# aif2 register map
Vendor: Texas Instruments
Registers are 32-bit, read-write, no defined reset value unless marked. A register's access mark holds for its fields unless they carry their own. Offsets are as the file gives them; [hi:lo] are bit positions; {n}, {i} and the like mark numbered series; 'fields as' and 'values as' point back to an identical list.

## AIF2 (part 3 of 3)
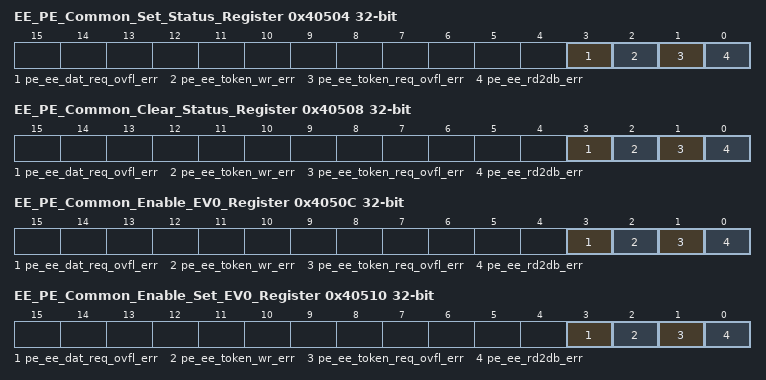
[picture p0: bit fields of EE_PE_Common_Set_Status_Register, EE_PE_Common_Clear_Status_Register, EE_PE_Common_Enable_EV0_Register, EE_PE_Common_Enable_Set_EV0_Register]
0x40504 EE_PE_Common_Set_Status_Register wo
  [3] pe_ee_dat_req_ovfl_err — PE data register overflow error Set.
  [2] pe_ee_token_wr_err — PE token write error Set.
  [1] pe_ee_token_req_ovfl_err — PE token register overflow error Set.
  [0] pe_ee_rd2db_err — PE read to DB error Set.
0x40508 EE_PE_Common_Clear_Status_Register wo
  [3] pe_ee_dat_req_ovfl_err — PE data register overflow error Clear.
  [2] pe_ee_token_wr_err — PE token write error Clear.
  [1] pe_ee_token_req_ovfl_err — PE token register overflow error Clear.
  [0] pe_ee_rd2db_err — PE read to DB error Clear.
0x4050C EE_PE_Common_Enable_EV0_Register ro — EE PE Common Enable EVO Register
  [3] pe_ee_dat_req_ovfl_err — PE data register overflow error Enable.
  [2] pe_ee_token_wr_err — PE token write error Enable.
  [1] pe_ee_token_req_ovfl_err — PE token register overflow error Enable.
  [0] pe_ee_rd2db_err — PE read to DB error Enable.
0x40510 EE_PE_Common_Enable_Set_EV0_Register wo
  fields as EE_PE_Common_Set_Status_Register
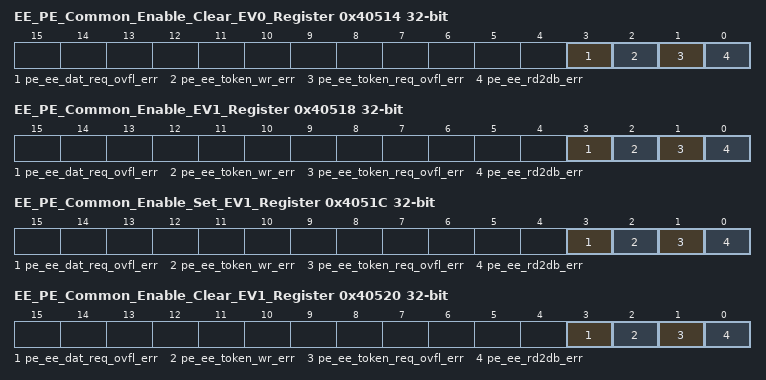
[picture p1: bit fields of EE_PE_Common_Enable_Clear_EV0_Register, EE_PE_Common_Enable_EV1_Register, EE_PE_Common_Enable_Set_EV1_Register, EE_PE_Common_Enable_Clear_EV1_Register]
0x40514 EE_PE_Common_Enable_Clear_EV0_Register wo
  fields as EE_PE_Common_Clear_Status_Register
0x40518 EE_PE_Common_Enable_EV1_Register ro
  fields as EE_PE_Common_Enable_EV0_Register
0x4051C EE_PE_Common_Enable_Set_EV1_Register wo
  [3] pe_ee_dat_req_ovfl_err — PE data register overflow error Enable Set.
  [2] pe_ee_token_wr_err — PE token write error Enable Set.
  [1] pe_ee_token_req_ovfl_err — PE token register overflow error Enable Set.
  [0] pe_ee_rd2db_err — PE read to DB error Enable Set.
0x40520 EE_PE_Common_Enable_Clear_EV1_Register wo
  [3] pe_ee_dat_req_ovfl_err — PE data register overflow error Enable Clear.
  [2] pe_ee_token_wr_err — PE token write error Enable Clear.
  [1] pe_ee_token_req_ovfl_err — PE token register overflow error Enable Clear.
  [0] pe_ee_rd2db_err — PE read to DB error Enable Clear.
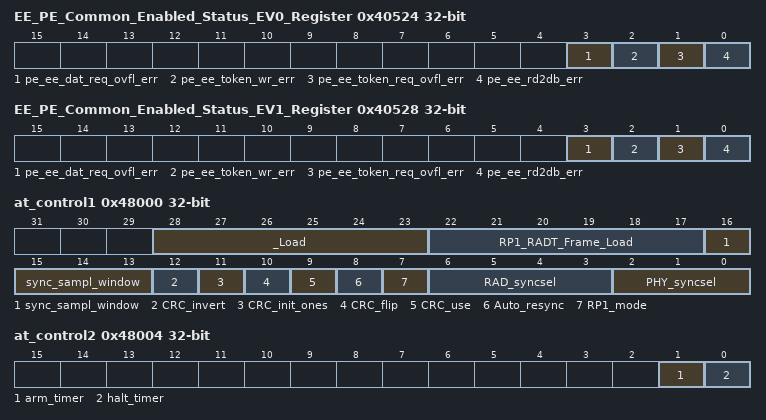
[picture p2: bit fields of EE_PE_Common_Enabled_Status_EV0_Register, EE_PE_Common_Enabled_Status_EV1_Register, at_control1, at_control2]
0x40524 EE_PE_Common_Enabled_Status_EV0_Register ro
  [3] pe_ee_dat_req_ovfl_err — PE data register overflow error Enabled.
  [2] pe_ee_token_wr_err — PE token write error Enabled.
  [1] pe_ee_token_req_ovfl_err — PE token register overflow error Enabled.
  [0] pe_ee_rd2db_err — PE read to DB error Enabled.
0x40528 EE_PE_Common_Enabled_Status_EV1_Register ro
  fields as EE_PE_Common_Enabled_Status_EV0_Register
0x48000 at_control1
  [28:23] _Load — RP1 PHYT Frame Load value =size +8
  [22:17] RP1_RADT_Frame_Load — RP1 RADT Frame Load value =size +8
  [16:13] sync_sampl_window — + or
  [12] CRC_invert
  [11] CRC_init_ones
  [10] CRC_flip — RP1 mode
  [9] CRC_use — CRC flip
  [8] Auto_resync — Auto resync if new frame boundary is received
  [7] RP1_mode
  [6:3] RAD_syncsel
  [2:0] PHY_syncsel
0x48004 at_control2
  [1] arm_timer, [0] halt_timer
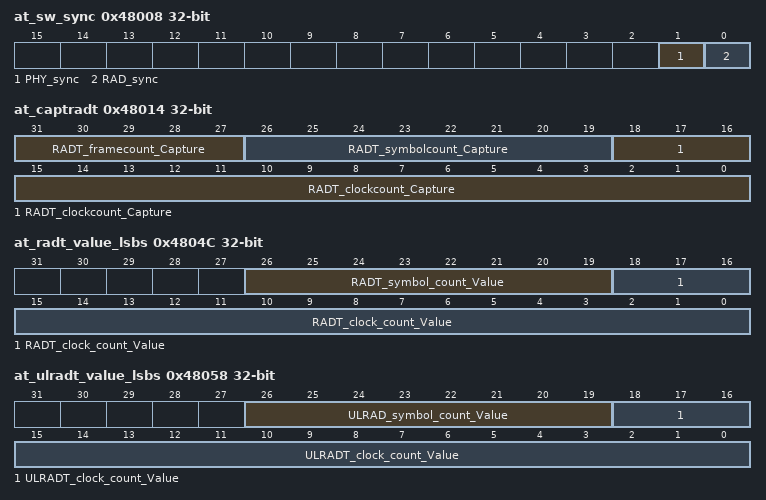
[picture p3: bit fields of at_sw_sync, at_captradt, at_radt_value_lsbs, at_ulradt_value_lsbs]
0x48008 at_sw_sync wo
  [1] PHY_sync, [0] RAD_sync
0x4800C at_phyt_cmp_radsync — at phyt radsync compare
  [21:0] RP1_RAD_Type_Select — PHYT_CMP PHYT compare value to produce a RADT sync when slected
0x48010 at_rp1_type
  [7:0] RP1_RAD_Type_Select
0x48014 at_captradt ro — Capture RADT clock and symbol and 5bit frame lsb counts on PHYT frame boundary
  [31:27] RADT_framecount_Capture — Capture RADT frame count 5lsbs upon a PHYT frame boundary
  [26:19] RADT_symbolcount_Capture — Capture RADT symbol count upon a PHYT frame boundary
  [18:0] RADT_clockcount_Capture — Capture RADT clock count upon a PHYT frame boundary
0x48020 at_rp1_type_capture ro
  [7:0] RP1_Type_Captured
0x48024 at_rp1_tod_capture_l ro
  [31:0] RP1_TOD_Capture_LSBs
0x48028 at_rp1_tod_capture_h ro
  [31:0] RP1_TOD_Capture_MSBs
0x4802C at_rp1_rp3_capture_l ro
  [31:0] RP1_RP3_Capture_LSBs
0x48030 at_rp1_rp3_capture_h ro
  [31:0] RP1_RP3_Capture_MSBs
0x48034 at_rp1_rad_capture_l ro
  [31:0] RP1_RADIO_System_Capture_LSBs
0x48038 at_rp1_rad_capture_h ro
  [31:0] RP1_RADIO_System_Capture_MSBs
0x48040 at_phyt_clkcnt_value ro
  [23:0] PHYT_clock_count_Value — PHYT clock count Value, 2 lsbs are always 00
0x48044 at_phyt_frm_value_lsbs ro
  [11:0] PHYT_Frame_Value_LSBs
0x48048 at_phyt_frm_value_msbs ro
  [27:0] PHYT_Frame_Value_MSBs
0x4804C at_radt_value_lsbs ro
  [26:19] RADT_symbol_count_Value, [18:0] RADT_clock_count_Value
0x48050 at_radt_value_mid ro
  [11:0] RADT_Frame_Value_LSBs
0x48054 at_radt_value_msbs ro
  [27:0] RADT_Frame_Value_MSBs
0x48058 at_ulradt_value_lsbs ro
  [26:19] ULRAD_symbol_count_Value — ULRADT symbol count Values
  [18:0] ULRADT_clock_count_Value
0x4805C at_ulradt_value_mid ro
  [11:0] ULRADT_Frame_Value_LSBs
0x48060 at_ulradt_value_msbs ro
  [27:0] ULRADT_Frame_Value_MSBs
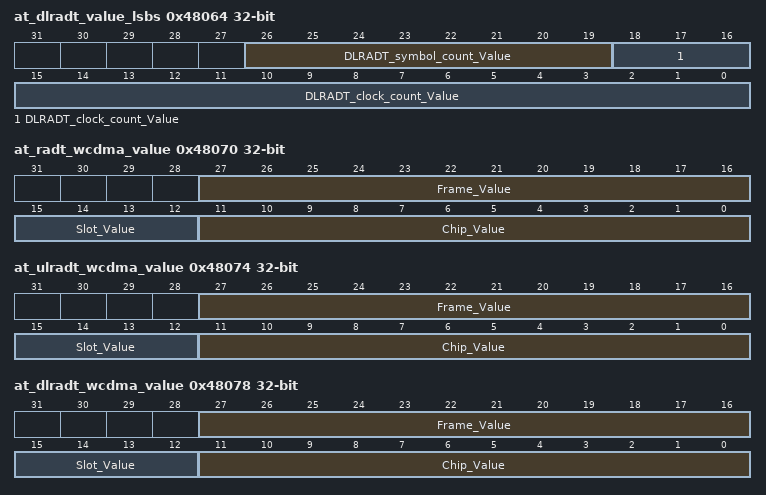
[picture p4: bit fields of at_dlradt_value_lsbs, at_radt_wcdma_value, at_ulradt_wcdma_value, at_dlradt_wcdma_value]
0x48064 at_dlradt_value_lsbs ro
  [26:19] DLRADT_symbol_count_Value, [18:0] DLRADT_clock_count_Value
0x48068 at_dlradt_value_mid ro
  [11:0] DLRADT_Frame_Value_LSBs
0x4806C at_dlradt_value_msbs ro
  [27:0] DLRADT_Frame_Value_MSBs
0x48070 at_radt_wcdma_value ro
  [27:16] Frame_Value, [15:12] Slot_Value, [11:0] Chip_Value
0x48074 at_ulradt_wcdma_value ro
  [27:16] Frame_Value, [15:12] Slot_Value, [11:0] Chip_Value
0x48078 at_dlradt_wcdma_value ro
  [27:16] Frame_Value, [15:12] Slot_Value, [11:0] Chip_Value
0x4807C at_radt_wcdma_div — at radt wcdma clock divider terminal count.
  [6:0] terminal_count — at radt wcdma clock divider terminal count. This counter divides dualbyte clock down to 3.84MHz chip rate for wcdma counters
0x48080 at_phyt_init_lsbs
  [21:0] PHYT_clock_count_Init
0x48084 at_phyt_init_mid
  [11:0] PHYT_Frame_Init_LSBs
0x48088 at_phyt_init_msbs
  [27:0] PHYT_Frame_Init_MSBs
0x4808C at_phyt_tc_lsbs
  [21:0] PHYT_Clock_Counter_TC
0x48090 at_phyt_frame_tc_lsbs
  [31:0] PHYT_Frame_TC_LSBs
0x48094 at_phyt_frame_tc_msbs
  [7:0] PHYT_Frame_TC_MSBs
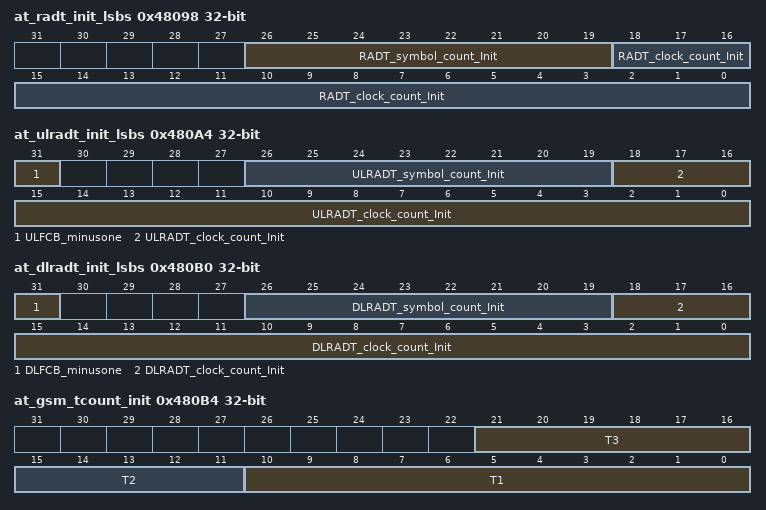
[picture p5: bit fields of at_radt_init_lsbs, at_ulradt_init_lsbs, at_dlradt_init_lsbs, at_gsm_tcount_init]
0x48098 at_radt_init_lsbs
  [26:19] RADT_symbol_count_Init, [18:0] RADT_clock_count_Init
0x4809C at_radt_init_mid
  [11:0] RADT_Frame_Init_LSBs
0x480A0 at_radt_init_msbs
  [27:0] RADT_Frame_Init_MSBs
0x480A4 at_ulradt_init_lsbs
  [31] ULFCB_minusone, [26:19] ULRADT_symbol_count_Init, [18:0] ULRADT_clock_count_Init
0x480A8 at_radt_tstamp_value ro
  [24:0] RADT_Tstamp_clock_counter_value
0x480B0 at_dlradt_init_lsbs
  [31] DLFCB_minusone, [26:19] DLRADT_symbol_count_Init, [18:0] DLRADT_clock_count_Init
0x480B4 at_gsm_tcount_init — at_gsm_tcount initialization
  [21:16] T3 — T3 w=init, affects at_gsm_tcount_value
  [15:11] T2 — T2 w=init, affects at_gsm_tcount_value
  [10:0] T1 — T1 w=init, affects at_gsm_tcount_value
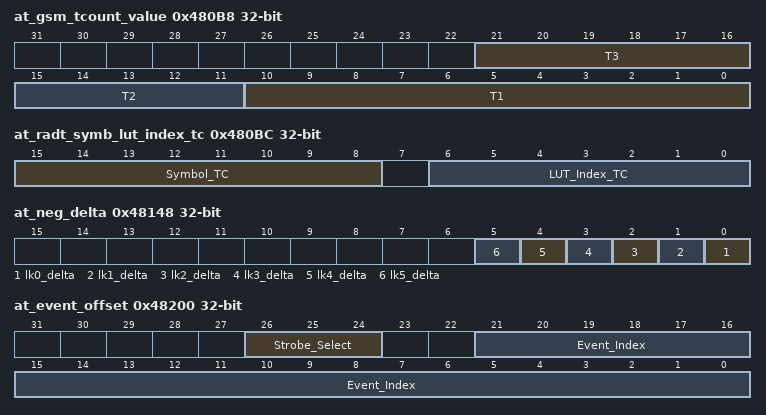
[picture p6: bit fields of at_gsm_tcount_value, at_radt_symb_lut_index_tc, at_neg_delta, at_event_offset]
0x480B8 at_gsm_tcount_value ro
  [21:16] T3 — T3 r=value of T3 counter
  [15:11] T2 — T2 r=value of T2 counter
  [10:0] T1 — T1 r=value of T1 counter
0x480BC at_radt_symb_lut_index_tc
  [15:8] Symbol_TC, [6:0] LUT_Index_TC
0x480C8 at_radt_frame_tc_lsbs — at_radt_frame_tc_msbs
  [31:0] RADT_Frame_TC_LSBs
0x480CC at_radt_frame_tc_msbs — at_radt_frame_tc_lsbs
  [7:0] RADT_Frame_TC_MSBs
0x480E0 at_ulradt_init_mid
  [11:0] RADT_Frame_Init_LSBs
0x480E4 at_ulradt_init_msbs
  [27:0] RADT_Frame_Init_MSBs
0x480E8 at_dlradt_init_mid
  [11:0] RADT_Frame_Init_LSBs
0x480EC at_dlradt_init_msbs
  [27:0] RADT_Frame_Init_MSBs
0x480F4 at_radt_init_lut_index — at_radt LUT Index initial value
  [6:0] LUT_Index_Init — LUT Index initial value
0x480F8 at_ulradt_init_lut_index — at_ulradt LUT Index initial value
  [6:0] LUT_Index_Init — LUT Index initial value
0x480FC at_dlradt_init_lut_index — at_dlradt LUT Index initial value
  [6:0] LUT_Index_Init — LUT Index initial value
0x48100 at_pimax_lk — (1 of 6, stride 12)
  [21:0] PI_max
0x48104 at_pimin_lk — (1 of 6, stride 12)
  [21:0] PI_min
0x48108 at_pivalue_lk ro — (1 of 6, stride 12)
  [21:0] PI_captured_value
0x48148 at_neg_delta — Negative delta control
  [n] lk{n}_delta (n=0..5) — Control for positive or negative delta for TM delta event. Controls the BFN PHYT frame number passed to the TM when the Delta event occurs
0x481F8 at_evt_enable
  [10:0] EVENT_Enable
0x481FC at_evt_force wo
  [10:0] EVENT_Force
0x48200 at_event_offset — (1 of 11, stride 16)
  [26:24] Strobe_Select
  [21:0] Event_Index — Event Offset Index
0x48204 at_event_mod_tc — (1 of 11, stride 16)
  [21:0] Event_Modulo
0x48208 at_event_mask_lsbs — (1 of 11, stride 16)
  [31:0] Event_Mask_LSBs
0x4820C at_event_mask_msbs — (1 of 11, stride 16)
  [31:0] Event_Mask_MSBs
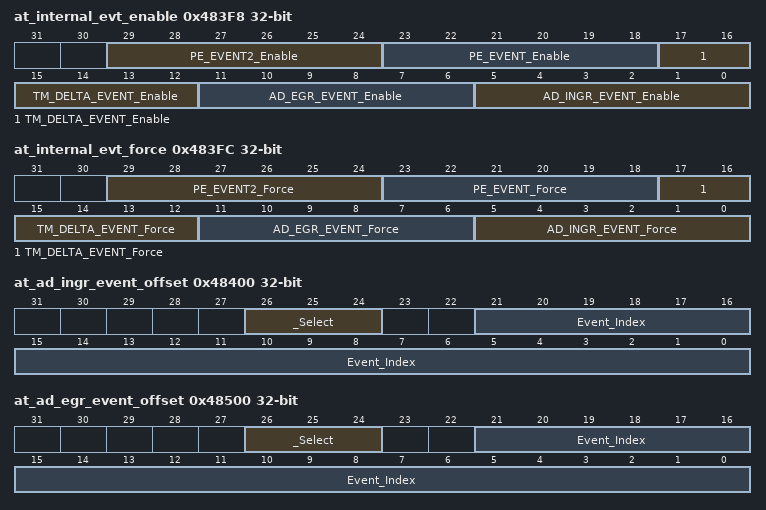
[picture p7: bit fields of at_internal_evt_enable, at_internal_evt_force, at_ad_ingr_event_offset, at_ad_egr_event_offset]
0x483F8 at_internal_evt_enable — at_internal_evt_enable. LSB for each field corresponds to the lowest event number for that field.
  [29:24] PE_EVENT2_Enable — PE at_pe_evt1 Enable. One event per link. LSB goes to link0, MSB to link5
  [23:18] PE_EVENT_Enable — PE at_pe_evt0 Enable . One event per link. LSB goes to link0, MSB to link5
  [17:12] TM_DELTA_EVENT_Enable — TM DELTA EVENT Enable. One event per link. LSB goes to link0, MSB to link5
  [11:6] AD_EGR_EVENT_Enable — AD Egress EVENT Enable. 3 pairs of events go to 3 AD egress engines. LSB of pair is Frame event
  [5:0] AD_INGR_EVENT_Enable — AD Ingress EVENT Enable. 3 pairs of events go to 3 AD ingress engines. LSB of pair is Frame event
0x483FC at_internal_evt_force wo
  [29:24] PE_EVENT2_Force — PE at_pe_evt1 Force
  [23:18] PE_EVENT_Force — PE at_pe_evt0 Force
  [17:12] TM_DELTA_EVENT_Force
  [11:6] AD_EGR_EVENT_Force — AD Egress EVENT Force
  [5:0] AD_INGR_EVENT_Force — AD Ingress EVENT Force
0x48400 at_ad_ingr_event_offset — (1 of 6, stride 8)
  [26:24] _Select
  [21:0] Event_Index — Event Offset Index
0x48404 at_ad_ingr_event_mod_tc — (1 of 6, stride 8)
  [21:0] _Modulo
0x48500 at_ad_egr_event_offset — (1 of 6, stride 8)
  [26:24] _Select
  [21:0] Event_Index — Event Offset Index
0x48504 at_ad_egr_event_mod_tc — (1 of 6, stride 8)
  [21:0] Event_Modulo
0x48540 at_tm_delta_event_offset — (1 of 6, stride 8)
  [21:0] Event_Offset — Event Offset Index
0x48544 at_tm_delta_event_mod_tc — (1 of 6, stride 8)
  [21:0] Event_Modulo
0x48580 at_pe_event_offset — (1 of 6, stride 8)
  [21:0] Event_Offset — Event Offset Index for at_pe_evt0
0x48584 at_pe_event_mod_tc — (1 of 6, stride 8)
  [21:0] Event_Modulo — Event Modulo for at_pe_evt0
0x485B0 at_pe_event2_offset — (1 of 6, stride 8)
  [21:0] Event_Offset — Event Offset Index for at_pe_evt1
0x485B4 at_pe_event2_mod_tc — (1 of 6, stride 8)
  [21:0] Event_Modulo — Event Modulo for at_pe_evt1
0x4A000 at_radt_sym_lut_ram — (1 of 128, stride 4)
  [18:0] radt_clock_tc — radt_sym
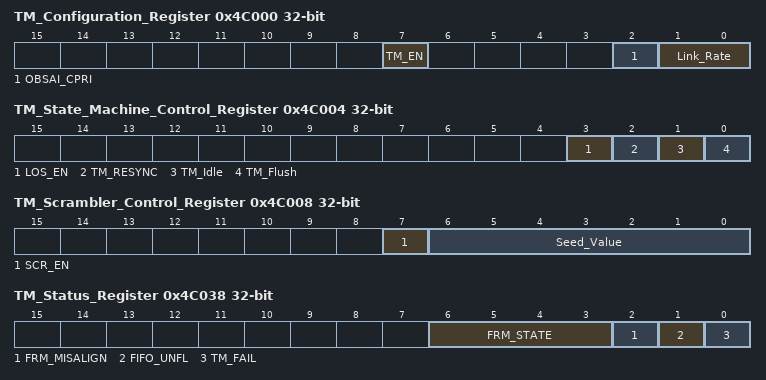
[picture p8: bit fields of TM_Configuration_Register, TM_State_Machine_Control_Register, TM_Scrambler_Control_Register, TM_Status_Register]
0x4C000 TM_Configuration_Register — (1 of 6, stride 2048)
  [7] TM_EN — The Transmit Enable Bit allows the TM block transmit state machine to operate. The following configurations
  [2] OBSAI_CPRI — The OBSAI/CPRI bit defines the mode of operation for the block. This bit should only be updated if TM Enable is 0
  [1:0] Link_Rate — The link rate field defines the rate of each link that each block will provide conversion. This field should only be updated if TM Enable is 0. The field can be programmed for the following rates
0x4C004 TM_State_Machine_Control_Register — (1 of 6, stride 2048)
  [3] LOS_EN — Allows Loss of Signal from the RM to cause the TM state machine to transition to the OFF state.
  [2] TM_RESYNC — Forces the Frame Sync state machine to transition from the FRAME_SYNC state to the RESYNC state and remain in the RESYNC state until the bit is cleared. If the state machine is in either the OFF state or the IDLE state, this bit is ignored until the state
  [1] TM_Idle — Forces the Frame Sync state machine to transition from either the FRAME_SYNC or RESYNC states to the IDLE state and remain in the IDLE state until the bit is cleared. If the state machine is in the OFF state, this bit is ignored until the state machine
  [0] TM_Flush — Instructs the TM link to flush the FIFO and force a TM Fail condition on the link. When set high, the State machine is forced into the RE_SYNC state
0x4C008 TM_Scrambler_Control_Register — (1 of 6, stride 2048)
  [7] SCR_EN — Enables the scrambler for operation in the transmit data path.
  [6:0] Seed_Value — The seed value is used to initialize the transmit scrambler circuit
0x4C00C TM_CPRI_L1_Inband_Configuration_Register — (1 of 6, stride 2048)
  [4:0] L1_Inband_CFG — Bit 0: RESET, Bit 1:RAI, Bit 2: SDI, Bit 3: LOS, Bit 4: LOF
0x4C010 TM_CPRI_L1_Inband_Enable_Register — (1 of 6, stride 2048)
  [8:0] L1_Inband_EN — Bit 8: LOS_LOSERR_EN, Bit 7: LOS_LOSRX_EN, Bit 6: LOF_LOFERR_EN, Bit 5: LOF_LOFRX_EN, Bit 4: RAI_LOSERR_EN, Bit 3: RAI_LOSRX_EN, Bit 2: RAI_LOFERR_EN, Bit 1: RAI_LOFRX_EN, Bit 0: RAI_RAIRX_EN
0x4C014 TM_CPRI_L1_Inband_LOSERR_Link_Select_Register — (1 of 6, stride 2048)
  [2:0] RM_Link_LOSERR — RM Link LOSERR Select
0x4C018 TM_CPRI_L1_Inband_LOFERR_Link_Select_Register — (1 of 6, stride 2048)
  [2:0] RM_Link_LOFERR — RM Link LOFERR Select
0x4C01C TM_CPRI_L1_Inband_LOSRx_Link_Select_Register — (1 of 6, stride 2048)
  [2:0] RM_Link_LOSRx — RM Link LOSRx Select
0x4C020 TM_CPRI_L1_Inband_LOFRx_Link_Select_Register — (1 of 6, stride 2048)
  [2:0] RM_Link_LOFRx — RM Link LOFRx Select
0x4C024 TM_CPRI_L1_Inband_RAIRx_Link_Select_Register — (1 of 6, stride 2048)
  [2:0] RM_Link_RAIRx — RM Link RAIRx Select
0x4C028 TM_CPRI_HFN_Status_Register ro — (1 of 6, stride 2048)
  [7:0] HFN — The Hyperframe number of the currently transmitting frame
0x4C02C TM_CPRI_Pointer_P_Configuration_Register — (1 of 6, stride 2048)
  [7:0] PTR_P — Pointer P value
0x4C030 TM_CPRI_Startup_Configuration_Register — (1 of 6, stride 2048)
  [7:0] STARTUP — Startup value
0x4C034 TM_CPRI_Protocol_Version_Configuration_Register — (1 of 6, stride 2048)
  [7:0] PROT_VERS — Protocol version value
0x4C038 TM_Status_Register ro — (1 of 6, stride 2048)
  [6:3] FRM_STATE — Indicates that status of the Frame Sync state machine
  [2] FRM_MISALIGN — CO Frame alignment mismatch from transmit FSM
  [1] FIFO_UNFL — Tx FIFO underflow
  [0] TM_FAIL — TM Fail condition met
0x4C03C TM_FRAME_MODE_Configuration_Register — (1 of 6, stride 2048)
  [0] FRM_MODE — Short Frame Enable
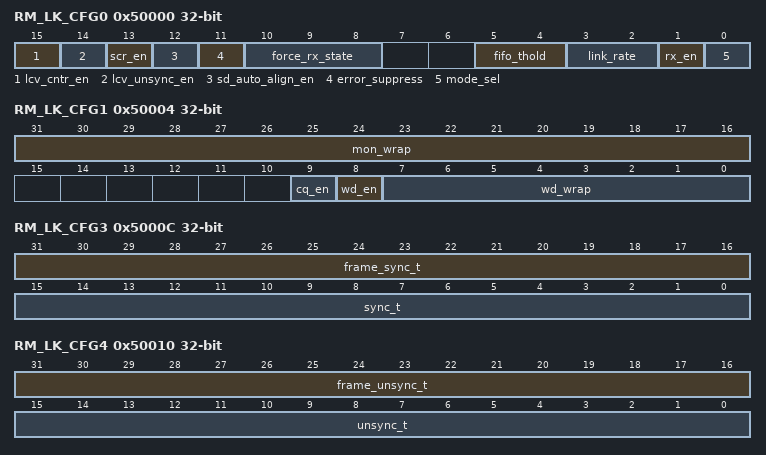
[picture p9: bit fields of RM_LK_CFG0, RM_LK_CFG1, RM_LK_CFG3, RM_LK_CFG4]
0x50000 RM_LK_CFG0 — (1 of 6, stride 2048)
  [15] lcv_cntr_en — Writing a 1 to the bit will enable the Line Code Violation counter. THis 16 bitt counter will saturate when it reaches a value of 0xffff. Writing a 0 to this bit will clear and disable the counter. The current counter value is available as status,
  [14] lcv_unsync_en — Enables a state transition from teh ST3 to the ST0 state when lcv_det_thold is met
  [13] scr_en — Enables the scrambler for operation in the receiver data path
  [12] sd_auto_align_en — Enables the RM to automatically disable Serdes symbol alignment when the receiver state machine reaches state ST3
  [11] error_suppress — Suppress error reporting when the receiver state machine is not in state ST3
  [10:8] force_rx_state — Force receiver state machine state
  [5:4] fifo_thold — Sets the watermark of where the RM begins reading from the RX FIFO
  [3:2] link_rate — The link rate field defines the rate of each link that each block
  [1] rx_en — Enable RM Link
  [0] mode_sel — Enables short frame mode for all six links
0x50004 RM_LK_CFG1 — (1 of 6, stride 2048)
  [31:16] mon_wrap — Defines the wrap value of the clock monitor used to define clock quality. A value of zero disables the clock monitor, Range 0 to 65,535
  [9] cq_en — Enables the clock quality circuit.
  [8] wd_en — Enables the clock detect watch dog timer.
  [7:0] wd_wrap — Defines the wrap value of the clock detection watchdog circuit. A value of zero disables the clock watchdog timer, Range 0 to 255
0x50008 RM_LK_CFG2 — (1 of 6, stride 2048)
  [15:0] los_det_thold — Sets 8b10b los detect threshold values in number of Line Code Violations received during a master frame, OBSAI, or during a Hyperframe, CPRI. Writing to this location will automatically clear the num_los counter and num_los_det status bit. Range 0 to
0x5000C RM_LK_CFG3 — (1 of 6, stride 2048)
  [31:16] frame_sync_t — Threshold value for consecutive valid message groups which result in state ST3. Range 0 to 65,535
  [15:0] sync_t — Threshold value for consecutive valid blocks of bytes which result in state ST1. Range 0 to 65,535
0x50010 RM_LK_CFG4 — (1 of 6, stride 2048)
  [31:16] frame_unsync_t — Threshold value for consecutive invalid message groups which result in state ST1. Range 0 to 65,535
  [15:0] unsync_t — Threshold value for consecutive invalid blocks of bytes which result in state ST0. Range 0 to 65,535
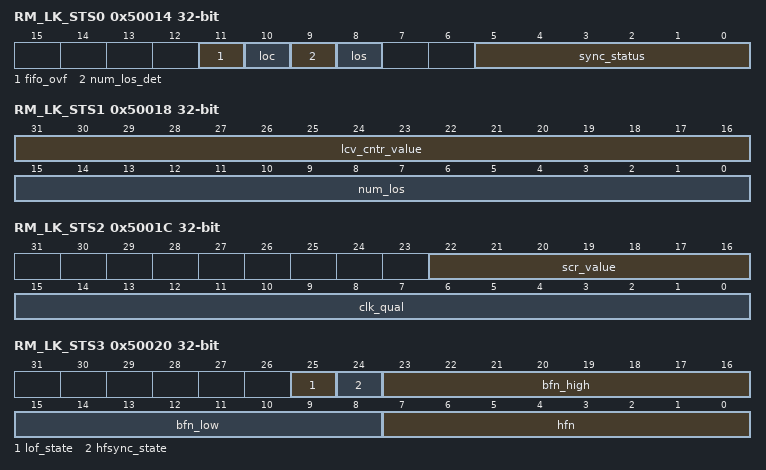
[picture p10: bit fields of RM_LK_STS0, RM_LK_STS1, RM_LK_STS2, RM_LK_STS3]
0x50014 RM_LK_STS0 ro — (1 of 6, stride 2048)
  [11] fifo_ovf — Active after an RM FIFO overflow
  [10] loc — The clock watchdog circuit detected a missing clock
  [9] num_los_det — Detects when num_los counter has reached the programable los_det_thold limit
  [8] los — Active when RX state machine is in ST0, inactive otherwise
  [5:0] sync_status — Indicates the surrent status of the RX state machine
0x50018 RM_LK_STS1 ro — (1 of 6, stride 2048)
  [31:16] lcv_cntr_value — Number of Line Code Violations counted since last cleared and enabled. Range 0 to 65,535
  [15:0] num_los — Represents the number of los_det, 8b10b code violation, occurrences in a mater frame, in OBSAI, or hyperframe, in CPRI. This counter will saturate and hold its value until either cleared by writing the configuration value los_det_thold =0 or after a
0x5001C RM_LK_STS2 ro — (1 of 6, stride 2048)
  [22:16] scr_value — Indicates the captured scrambling code, only when configuration bit scr_en =1.
  [15:0] clk_qual — A value that represents the quality, relative frequency, of the received Serdes clock. Range 0 to 65,535
0x50020 RM_LK_STS3 ro — (1 of 6, stride 2048)
  [25] lof_state — Active high status indicates Loss Of Frame when the receiver FSM is in state ST0 or ST1. NOTE.. The value of this bit will be 0 after reset but will change to a value of 1 if CPRI mode is enabled.
  [24] hfsync_state — Active high status indicates when the receiber FSM is in the HFSYNC state ST3
  [23:16] bfn_high — Received Node B Frame number high byte, Z.130.0
  [15:8] bfn_low — Received Node B Frame number low byte, Z.128.0
  [7:0] hfn — Received hyperframe number, Z.64.0. Range 0 to 149 basic frames
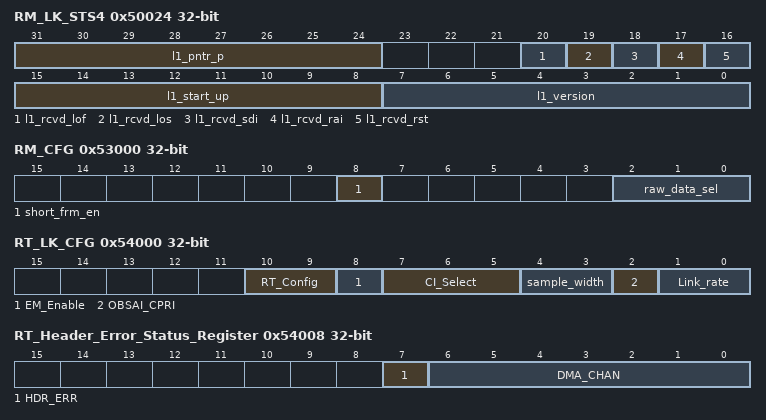
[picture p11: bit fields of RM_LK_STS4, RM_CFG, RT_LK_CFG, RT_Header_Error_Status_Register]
0x50024 RM_LK_STS4 ro — (1 of 6, stride 2048)
  [31:24] l1_pntr_p — Received Pointer P
  [20] l1_rcvd_lof — Received sdi, Z.130.0, b4
  [19] l1_rcvd_los — Received sdi, Z.130.0, b3
  [18] l1_rcvd_sdi — Received sdi, Z.130.0, b2
  [17] l1_rcvd_rai — Received rai, Z.130.0, b1
  [16] l1_rcvd_rst — Received reset, Z.130.0, b0
  [15:8] l1_start_up — Received start up information, Z.66.0
  [7:0] l1_version — Received protocol version, Z.2.0
0x53000 RM_CFG — RM Configuration Register
  [8] short_frm_en — Short Frame enable
  [2:0] raw_data_sel — Select 1 of 6 links of raw, not gated, RM output data used for data trace feature
0x54000 RT_LK_CFG — (1 of 6, stride 2048)
  [10:9] RT_Config — The RT Configuration field configures the mode of operation of the RT block.
  [8] EM_Enable — The Empty Message Enable Bit configures the RT block to insert an empty message in the event that a message is discovered to have a code violation in the header. The configuration is valid in OBSAI mode only.
  [7:5] CI_Select — The CI Select bits indicate the selected link for the retransmitted data path.
  [4:3] sample_width — The Sample Width field defines the sample size of the antenna carriers within a CPRI frame.
  [2] OBSAI_CPRI — The OBSAI_CPRI bit defines the mode of operation for the block.
  [1:0] Link_rate — The link rate field defines the rate of each link that each block will provide conversion.
0x54004 RT_FIFO_Depth_Status_Register ro — (1 of 6, stride 2048)
  [7:0] RT_DEPTH — Describes the Current FIFO Depth
0x54008 RT_Header_Error_Status_Register ro — (1 of 6, stride 2048)
  [7] HDR_ERR — Indicates an Error has Occurred
  [6:0] DMA_CHAN — Defines DMA Channel of Error
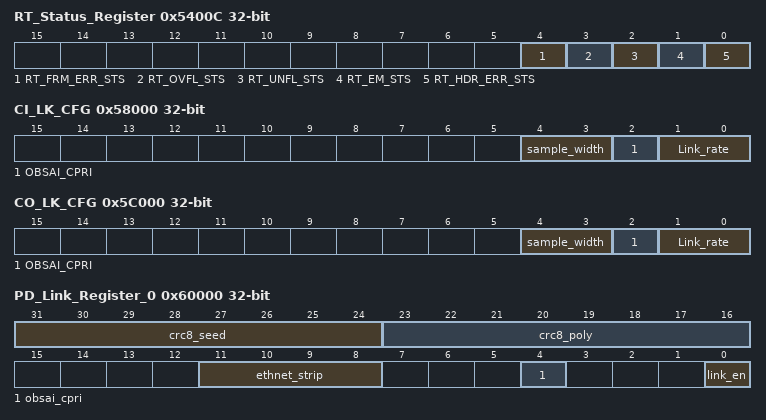
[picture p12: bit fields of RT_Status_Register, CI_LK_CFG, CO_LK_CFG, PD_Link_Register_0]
0x5400C RT_Status_Register ro — (1 of 6, stride 2048)
  [4] RT_FRM_ERR_STS — Indicates a frame error of the FIFO has occurred
  [3] RT_OVFL_STS — Indicates an Overflow of the FIFO has occurred
  [2] RT_UNFL_STS — Indicates an Underflow of the FIFO has occurred
  [1] RT_EM_STS — Indicates an empty message was inserted
  [0] RT_HDR_ERR_STS — Indicates a header error has occurred
0x58000 CI_LK_CFG — (1 of 6, stride 2048)
  [4:3] sample_width — The Sample Width field defines the sample size of the antenna carriers within a CPRI frame.
  [2] OBSAI_CPRI — The OBSAI_CPRI bit defines the mode of operation for the block.
  [1:0] Link_rate — The link rate field defines the rate of each link that each block will provide conversion.
0x5C000 CO_LK_CFG — (1 of 6, stride 2048)
  fields as CI_LK_CFG
0x60000 PD_Link_Register_0 — (1 of 6, stride 2048)
  [31:24] crc8_seed — CRC8: programmable starting seed value (CRC16 and CRC32 seed is fixed)
  [23:16] crc8_poly — CRC8: programmable polynomial for CRC8 (CRC16 and CRC32 polynomials are fixed)
  [11:8] ethnet_strip — CPRI: bit3-0 enables stripping Ethernet headers for chan3-0 OBSAI: unused
  [4] obsai_cpri — OBSAI or CPRI mode of operation.
  [0] link_en — Link Enable.
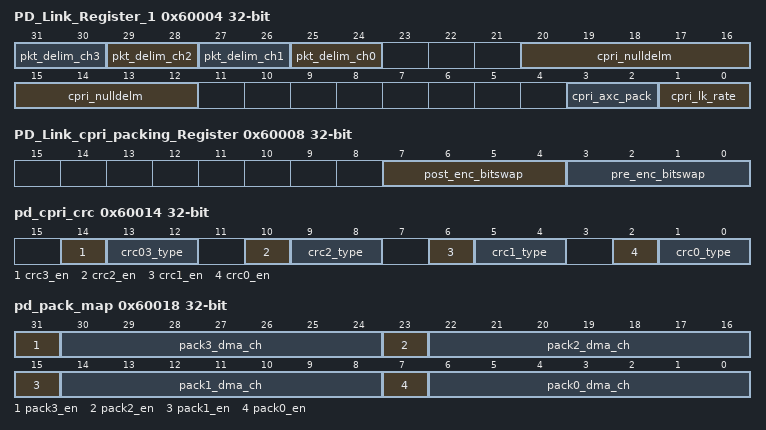
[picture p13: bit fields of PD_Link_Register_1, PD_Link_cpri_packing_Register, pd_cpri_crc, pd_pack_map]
0x60004 PD_Link_Register_1 — (1 of 6, stride 2048)
  [2n+25:2n+24] pkt_delim_ch{n} (n=0..3) — CRPI Control Word 4B/5B encoding enable
  [20:12] cpri_nulldelm — CPRI Conrol Word Null Delimitor. Used instead of 4B/5B for packet delimitation. Only used when enabled by above fields
  [3:2] cpri_axc_pack — CRPI: identifies the bit precision of the IQ data. Used to un-packing packet data passed over CPRI AxC slots
  [1:0] cpri_lk_rate — CPRI link rate (na for OBSAI).
0x60008 PD_Link_cpri_packing_Register — (1 of 6, stride 2048)
  [7:4] post_enc_bitswap — Swaps bits in bytes after 4B,5B,Null decoders. 1 bit for each of the 4 channels.
  [3:0] pre_enc_bitswap — Swaps bits in bytes before 4B,5B,Null decoders. 1 bit for each of the 4 channels.
0x60014 pd_cpri_crc — (1 of 6, stride 2048)
  [14] crc3_en — (same) CPRI Packt Stream 3
  [13:12] crc03_type — (same) CPRI Packt Stream 3
  [10] crc2_en — (same) CPRI Packt Stream 2
  [9:8] crc2_type — (same) CPRI Packt Stream 2
  [6] crc1_en — (same) CPRI Packt Stream 1
  [5:4] crc1_type — (same) CPRI Packt Stream 1
  [2] crc0_en — CRC: enable CRC check on type-by-type basis.
  [1:0] crc0_type — CRC: length of CRC.
0x60018 pd_pack_map — (1 of 6, stride 2048)
  [31] pack3_en — Enables usage of pack3 circuit. When diabled, 0x1, data is dropped on the floor without capture to a DMA channel
  [30:24] pack3_dma_ch — When enabled, indicates which DMA channel should be associated with this stream
  [23] pack2_en — same... pack2
  [22:16] pack2_dma_ch — same... pack2
  [15] pack1_en — same... pack1
  [14:8] pack1_dma_ch — same... pack1
  [7] pack0_en — same... pack0
  [6:0] pack0_dma_ch — same... pack0
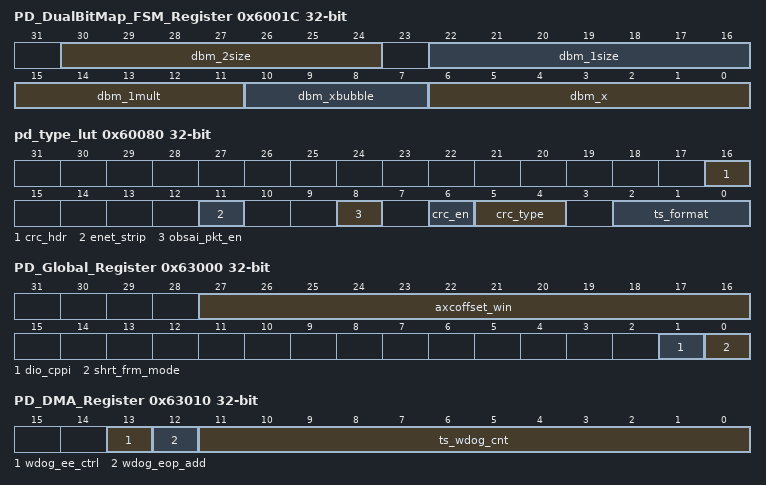
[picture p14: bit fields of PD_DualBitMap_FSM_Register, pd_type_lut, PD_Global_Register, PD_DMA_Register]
0x6001C PD_DualBitMap_FSM_Register — (1 of 6, stride 2048)
  [30:24] dbm_2size — DBMF number of bits of bit map2 to use.
  [22:16] dbm_1size — DBMF number of bits of bit map1 to use.
  [15:11] dbm_1mult — DBMF repititions of map1.
  [10:7] dbm_xbubble — DBMF bubble count where 0:indicates 1 bubble of 1 AxC sample (4bytes). OBSAI DBMF assumes 4 AxC samples as a bubble length. A burst of bubbles is inserted only when dictated to do so by the bit maps. This field gives great flexibility in rate matching
  [6:0] dbm_x — CPRI Dual Bit Map FSM (DBMF) channel count, sets the max number of AxC supported in a given Link. i.e. for CPRI 4x LTE15MHz this must be set to 7b'0000001 indicating 2 AxC
0x60020 PD_DualaBitMap_Bit_Map_1 — (1 of 6, stride 2048)
  [31:0] dbm_1map — bit-by-bit bit map \[99:0\]. pd_dbm_1map\[0\].dbm_1map\[0\] ==bit 0 of 100 bits
0x60030 PD_DualaBitMap_Bit_Map_2 — (1 of 6, stride 2048)
  [31:0] dbm_2map — bit-by-bit bit map \[67:0\]. pd_dbm_2map\[0\].dbm_2map\[0\] ==bit 0 of 68 bits
0x60080 pd_type_lut — (1 of 6, stride 2048)
  [16] crc_hdr — CRC16 is calucalted over OBSAI header as well as payload (only valid for OBSAI TYPES CONTROL (0x0) and MEASUREMENT (0x1)
  [11] enet_strip — 0x0: No Strip 0x1: Strip off the first 8 bytes of each packet. Purpose is to strip the ethernet preamble and SOP. PD blindly strips without checking content of 8 bytes. CRC is not calculated over stripped bytes.
  [8] obsai_pkt_en — Used to determine if PD should
  [6] crc_en — CRC: enable CRC check on type-by-type basis.
  [5:4] crc_type — CRC: length of CRC.
  [2:0] ts_format — TS: OBSAI time stamp check (n/a CPRI)
0x63000 PD_Global_Register — Fields which are global for the entire PD
  [27:16] axcoffset_win — OBSAI reception timing window width parameter. Indicates the window size for searching the radio frame boundary identified by TS=0. Minimum WCDMA value is (320/2 + 80)
  [1] dio_cppi — For streams that are AxC, use DB as a circular RAM which will feed DIO DMA. (WCDMA use DIO) otherwise, DB is used as a FIFO for AxC traffic and will feed CPPI DMA. (For packet streams, this fields has no impact)
  [0] shrt_frm_mode — Short Frame mode, used for HW test # only. Shortens the OBSAI and CPRI frames for purposes of reducing simulation time.
0x63004 PD_Global_Enable_Set_Register wo — Set Global Enable for PD
  [31:0] DONT_CARE — A write of any value to this register which sets (enables) global enable
0x63008 PD_Global_Enable_Clear_Register wo — Clear Global Enable for PD
  [31:0] DONT_CARE — A write of any value to this register which clears (enables) global enable
0x6300C pd_global_en_sts ro — Read Only status of global enable state. Even if this register is OFF, PD may still be closing out packets.
  [0] enable — 0x1: PD_ON 0x0:PD_OFF
0x63010 PD_DMA_Register — Controls DMA funcationality which is common ammong all links
  [13] wdog_ee_ctrl — Report every missed WDog fail, or report only fails of missing EOP
  [12] wdog_eop_add — Controls circuit to simply report or to report and add an EOP if the WDog fails on an expected EOP. ADD_EOP is only a valid choice for OBSAI GSM type traffic where there is no incoming data during TDD=0 time slots. All other standards have null traffic to
  [11:0] ts_wdog_cnt — OBSAI Watch Dog Count Duration. Counts in 307.2 MHz SYS Clock. Terminal Count must be reach approximately 3 times before Timer fails
0x63014 PD_RadT_Terminal_Count — OBSAI timing control, RadT usage (used for OBSAI LTE and WiMax)
  [24:0] radt_tc — Max expected value for the RadT timer value. Used for creating a exected timing window (for which TS=0 marks a Radio Frame Boundary)
0x63020 PD_Channel_Status_Registers ro — (1 of 4, stride 4)
  [31:0] chan_on — 0x1: CHAN_ON 0x0:CHAN_OFF
0x63030 PD_Packet_Status_Registers ro — (1 of 4, stride 4)
  [31:0] chan_pkt — Channel is currently in the middle of a packet. Channel will not turn off even if disabled.
0x63040 PD_Frame_Terminal_Count — (1 of 6, stride 4)
  [23:16] frm_sym_tc — Radio framing counter. Symbol terminal count.
  [15:8] frm_index_sc — Radio framing counter. Index Start count.
  [7:0] frm_index_tc — Radio framing counter. Index Terminal count.
0x63400 PD_Routing_Register — (1 of 128, stride 4)
  [29:28] route_mask — Reception Routing: controls how many OBSAI time stamp bits to use in the reception routing.
  [26:24] route_lk — Reception Routing: Link number for which to apply this routing rule.
  [23:11] route_adr — Reception Routing: OBSAI address.
  [10:6] route_type — Reception Routing: OBSAI type.
  [5:0] route_ts — Reception Routing: OBSAI time stamp. Used to extend addressing by using the TS field. (Only known use is for OBSAI Generic Packet type and Control Packet type) The number of bits of TS to compare is controlled via the ctrl field.
0x63600 PD_x128_DMA_Channel_Config_Register — (1 of 128, stride 4)
  [8] data_format
  [0] chan_en — Channel On/Off. Schedules a channel to be turned on or off. For AxC traffic, Channel will turn On/Off on next Radio Frame Boundary. For Packet Traffic, Channel will turn On/Off once channel is in EOP state, competeling any packet which may currently be
0x64000 PD_x128_DMA_Channel_Config_0_Register — (1 of 128, stride 4)
  [24:0] axc_offset — OBSAI: Antenna Carrier offset programmed in 307.2MHz clocks and relative to the Frame Boundary of the RadT AT timer. Specifies the center of the receive window for an AxC offset (typical WCDMA value of (4chip_offset x 320) + 320/2) CPRI: Antenna Carrier
0x64200 PD_x128_DMA_Channel_Config_1_Register — (1 of 128, stride 4)
  [31:16] tdd_en — PD TDD Sym15-to-0, disables DMA of whole symbols (CPPI packets), Program as 0xffff for most applications Bit mapped, bit0
  [15:12] dio_offset — Offset for DIO DMA mode. Used to align DMA for AxC with differing AxC offsets.
  [7:5] frm_grp — OBSAI framing counter: Which of 6 framing counter terminal counts should be used for each dma channel. (codes 3'b110 and 3'b111 are reserved)
  [4] gsm_ul — Data Format
  [0] ts_wdog_en — TS: enable OBSAI time stamp watch dog
{0x64000+0x200*i} PD_x128_DMA_Channel_Config_{i}_Register (i=2..5) — (1 of 128, stride 4)
  [31:0] tdd_en — PD TDD Sym{32i-48}-to-{32i-17}, disables DMA of whole symbols (CPPI packets), Program as 0xffff for most applications Bit mapped, bit0
0x64C00 pd_frm_msg_tc — (1 of 128, stride 4)
  [15:0] frme_msg_tc — Radio AxC framing counter. nx4 sample count (OBSAI equal to message count).
0x68000 PE_Link_Register — (1 of 6, stride 2048)
  [28:24] mem_fetch_delay — delay (in sys_clks) between DB read and PE processing. Gives time for DB RAM fetch prior to message construction. Nominally programmed OBSAI==28 CPRI==0.
  [20] obsai_bubble_bw — OBSAI Only. DBM rule Bubbles are used for traffic. Channel is indicated by 64th location of Channel Rule LUT. Recommended for Pkt traffic only and recommended only for cases where XCNT is less than 64
  [17:16] lk_rate — Link rate (5x na for OBSAI).
  [4] obsai_cpri — OBSAI or CPRI mode of operation.
  [3] gsm_compress — GSM OBSAI is only suppling some DMA data for each GSM Time Slot. AIF2_PE will not consider this an error, will insert OBSAI empty message in the gaps, and will sync up to the beginning of the next GSM Time Slot
  [2] tdd_axc — AIF2 is tollerant of whole symbols of missing data on AxC-by-AxC basis. In TDD, SW is permitted to have gaps of whole symbols. (Also support for Base Band hopping of GSM antenna carriers. SW manages which antenna each symbol is sent to.)
  [1] dio_cppi — All AxC within the link are treated as DIO traffic. Packets still remain as CPPI traffic.
  [0] lk_en — Link Enable
0x68004 PE_CRC_Register — (1 of 6, stride 2048)
  [15:8] crc8_seed — CRC8: programmable starting seed value (CRC16 and CRC32 seed is fixed)
  [7:0] crc8_poly — CRC: programmable polynomial for CRC8 (other polynomials are fixed)
0x68008 PE_CPRI_DualBitMap_FSM_Register — (1 of 6, stride 2048)
  [30:24] cpri_dbm_2size — DBMF number of bits of bit map2 to use.
  [22:16] cpri_dbm_1size — DBMF number of bits of bit map1 to use.
  [15:11] cpri_dbm_1mult — DBMF repititions of map1.
  [10:7] cpri_dbm_xbubble — DBMF bubble count where 0:indicates 1 bubble of 1 AxC sample. OBSAI DBMF assumes 4 AxC samples as a bubble length. A burst of bubbles is inserted only when dictated to do so by the bit maps. This field gives great flexibility in rate matching
  [6:0] cpri_dbm_x — CPRI Dual Bit Map FSM (DBMF) channel count, sets the max number of AxC supported in a given Link. i.e. for CPRI 4x LTE15MHz this must be set to 7b'0000001 indicating 2 AxC
0x6800C PE_CPRI_Encoder_Bitswap_Register — (1 of 6, stride 2048)
  [7:4] post_enc_bitswap — CPRI post_enc_bitswap swaps bits in bytes after 4B,5B,Null encoders. 1 bit for each of the 4 channels.
  [3:0] pre_enc_bitswap — CPRI pre_enc_bitswap swaps bits in bytes before 4B,5B,Null encoders. 1 bit for each of the 4 channels.
0x68010 pe_cpridbm_1map — (1 of 6, stride 2048)
  [31:0] cpri_dbm_1map — DBMF bit map1.
0x68020 pe_cpridbm_2map — (1 of 6, stride 2048)
  [31:0] cpri_dbm_2map — DBMF bit map2.
0x6802C PE_CPRI_Link_Register_1 — (1 of 6, stride 2048)
  [2n+25:2n+24] pkt_delim_ch{n} (n=0..3) — CRPI Control Word 4B/5B encoding enable
  [20:12] cpri_nulldelm — CPRI Conrol Word Null Delimitor. Used instead of 4B/5B for packet delimitation. Only used when enabled by above fields
  [1:0] cpri_axc_pack — CRPI: identifies the bit precision of the IQ data. Used to un-packing packet data passed over CPRI AxC slots
0x68030 PE_CPRI_Link_Register_2 — (1 of 6, stride 2048)
  [31] cpri_pkt3_ch_en — Enables usage of pack3 circuit. When diabled, 0x1, data is dropped on the floor without capture to a DMA channel
  [30:24] cpri_pkt3_ch — When enabled, indicates which DMA channel should be associated with this stream
  [23] cpri_pkt2_ch_en — same... pack2
  [22:16] cpri_pkt2_ch — same... pack2
  [15] cpri_pkt1_ch_en — same... pack1
  [14:8] cpri_pkt1_ch — same... pack1
  [7] cpri_pkt0_ch_en — same... pack0
  [6:0] cpri_pkt0_ch — same... pack0
0x68400 pe_cpri_cw_lut — (1 of 6, stride 2048)
  [2] cw_en — All possible CPRI CW per hyperframe. Dicatates whether the control word should be captured at all
  [1:0] cw_chan — All possible CPRI CW per hyperframe are are mapped to one of four CPRI CW staging areas. This allow CPRI CW to be split into 4 differen streams.
0x6C000 PE_Global_Register
  [12] dio_len — DirectIO buffer length, set same as value in DB
  [8] enet_hdr_sel — bit order for Ethernet preamble and SOF 0: 0xAAAAAAAB 1: 0x555555D5
  [6:4] token_phase — Gives Phase alignement relative to Channel Radio Frame Boundary for scheduling DMA. OBSAI: only lsb is used CPRI: all three bits give 8th phase alignment. Phase can be used to adjust DMA according to DMA transfer budget.
  [0] shrt_frm_mode — Short Frame mode, used for HW test # only. Shortens the OBSAI and CPRI frames for purposes of reducing simulation time.
0x6C004 PE_Global_Enable_Set_Register wo — Set Global Enable for PE
  fields as PD_Global_Enable_Set_Register
0x6C008 PE_Global_Enable_Clear_Register wo — Clear Global Enable for PE
  fields as PD_Global_Enable_Clear_Register
0x6C00C PE_global_en_sts ro — Read Only status of global enable state. Even if this register is OFF, PE may still be closing out packets.
  [0] enable — 0x1: pe_ON 0x0:pe_OFF
0x6C010 PE_Channel_Status_Registers ro — (1 of 4, stride 4)
  [31:0] chan_on_sts — 0x1: CHAN_ON 0x0:CHAN_OFF
0x6C020 PE_Packet_Status_Registers ro — (1 of 4, stride 4)
  [31:0] pkt_sts — 0x1: IN_PKT 0x0:OUT_PKT
0x6C080 PE_Frame_Count_Register — (1 of 6, stride 4)
  [23:16] frm_sym_tc — OBSAI/CPRI radio framing counter. Symbol terminal count.
  [14:8] frm_index_sc — OBSAI/CPRI radio framing counter. Index Start count.
  [6:0] frm_index_tc — OBSAI/CPRI radio framing counter. Index Terminal count.
0x6C200 PE_DMA_Channel_Enable_Register — (1 of 128, stride 4)
  [0] ch_en — Enable channels one-by-one
0x6C400 PE_DMA_Channel_0_Register — (1 of 128, stride 4)
  [16] crc_hdr — CRC16 is calucalted over OBSAI header as well as payload (only valid for OBSAI TYPES CONTROL (0x0) and MEASUREMENT (0x1)
  [12] ethernet — Channel is ethernet. This field controls insertion of the Ethernet Premble and SOF
  [10:9] crc_type — CRC: length of CRC
  [8:7] rt_ctl — Controls RT to perform appropriate insterion/aggregation into PHY
  [6:4] frm_tc — OBSAI/CPRI framing counter: Which of 6 framing counter terminal counts should be used for each dma channel. (codes 3b110 and 3b111 are reserved)
  [0] crc_en — CRC: enable CRC check on AxC by AxC basis
0x6C600 PE_Input_FIFO_Control — (1 of 128, stride 4)
  [23:16] sync_sym — Normally set to 0. First non-tdd symbol of frame. Used for startup sync with DMA.
  [7:4] mf_full_lev — Message Constuction FIFO: Set full level per channel. Full level controls halt of data fetch to prevent overflow.
  [3:0] mf_wmark — Message Constuction FIFO: Set water mark per channel. Water mark controls fill level for which lower/higher fetch rate is issued
0x6C800 PE_Antenna_Carrier_Offset — (1 of 128, stride 4)
  [24:0] axc_offset — Antanna carrier offset. Programmed in sys-clocks relative to the radio frame boundary.
0x6CA00 PE_AxC_Framing_Counter_Register — (1 of 128, stride 4)
  [15:0] frme_msg_tc — OBSAI AxC framing counter. Number of OBSAI messages (16 bytes) per radio symbol
0x6CC00 PE_Modulo_Terminal_Count_Register — (1 of 64, stride 4)
  [30:28] rule_lk — Indicates which link the rule is allocated to
  [27:16] rule_index — Index. Transmission Rule. Index indicates at which count the rule will fire.
  [13] rule_ctl_msg — 1: Module Rule oppeations on OBSAI control messages 0: AxC messages
  [12] rule_en — Transmission Rule Enable.
  [11:0] rule_mod — Modulo Terminal count of the rule counter. Dictates the period of the rule. Terminal count is the OBSAI Module minus 1.
0x6CE00 PE_DMA_Channel_OBSAI_HDR_Register — (1 of 128, stride 4)
  [30] bb_hop — OBSAI Address is taken from CPPI protocol specific bits (SW value passed in data dma) instead of obsai_adr mmr bits
  [29] obsai_pkt — OBSAI channel (not used for CPRI) is a packet channel not AxC channel. AxC traffic is given higher DMA priority than Pkt traffic.
  [28:26] obsai_ts_frmt — TS: OBSAI time stamp generation algorithm
  [25:24] obsai_ts_mask — Controls which parts of the OBSAI TS field are inserted vs. calculated
  [23:11] obsai_adr — OBSAI hdr(23:11)ADR : inserted into OBSAI header ADDRESS field
  [10:6] obsai_type — OBSAI hdr(10:6) TYPE: inserted int OBSAI header TYPE field
  [5:0] obsai_ts_adr — OBSAI hdr( 5:0) TS : only used if TS is inserted instead of generated
0x70000 PE_DBMF_Register — (1 of 64, stride 4)
  [30:24] dbm_2size — DBMF number of bits of bit map2 to use.
  [22:16] dbm_1size — DBMF number of bits of bit map1 to use.
  [12:8] dbm_1mult — DBMF repititions of map1
  [6:0] dbm_x — DBMF max number of supported channels
0x70800 PE_OBSAI_DBMF_Bit_Map_1_and_2_Register — (1 of 512, stride 4)
  [31:0] dbm_bit_map — DBMF bit map 1and2
{0x74000+0x800*i} PE_Channel_Rule_LUT_{i} (i=0..5) — (1 of 512, stride 4)
  [8] cpri_pkt_en — DBMF CPRI Stream LUT: dicates the cpri payload is to be used as AxC (normal) or Packet traffic. (note: the concept of packet traffic in CPRI payload is a feature extention of CPRI)
  [7] chanindex_en — enable entry
  [6:0] chanindex — DMA channel number, LUT maps rule indexes to DMA channels (CPRI 0-3 packet channel if cpri_pkt_en=1)
0x77000 PE_Channel_Rule_LUT_6 — (1 of 512, stride 4)
  [7] chanindex_en — enable entry
  [6:0] chanindex — DMA channel number, LUT maps rule indexes to DMA channels
0x77800 PE_Channel_Rule_LUT_7 — (1 of 512, stride 4)
  fields as PE_Channel_Rule_LUT_6
